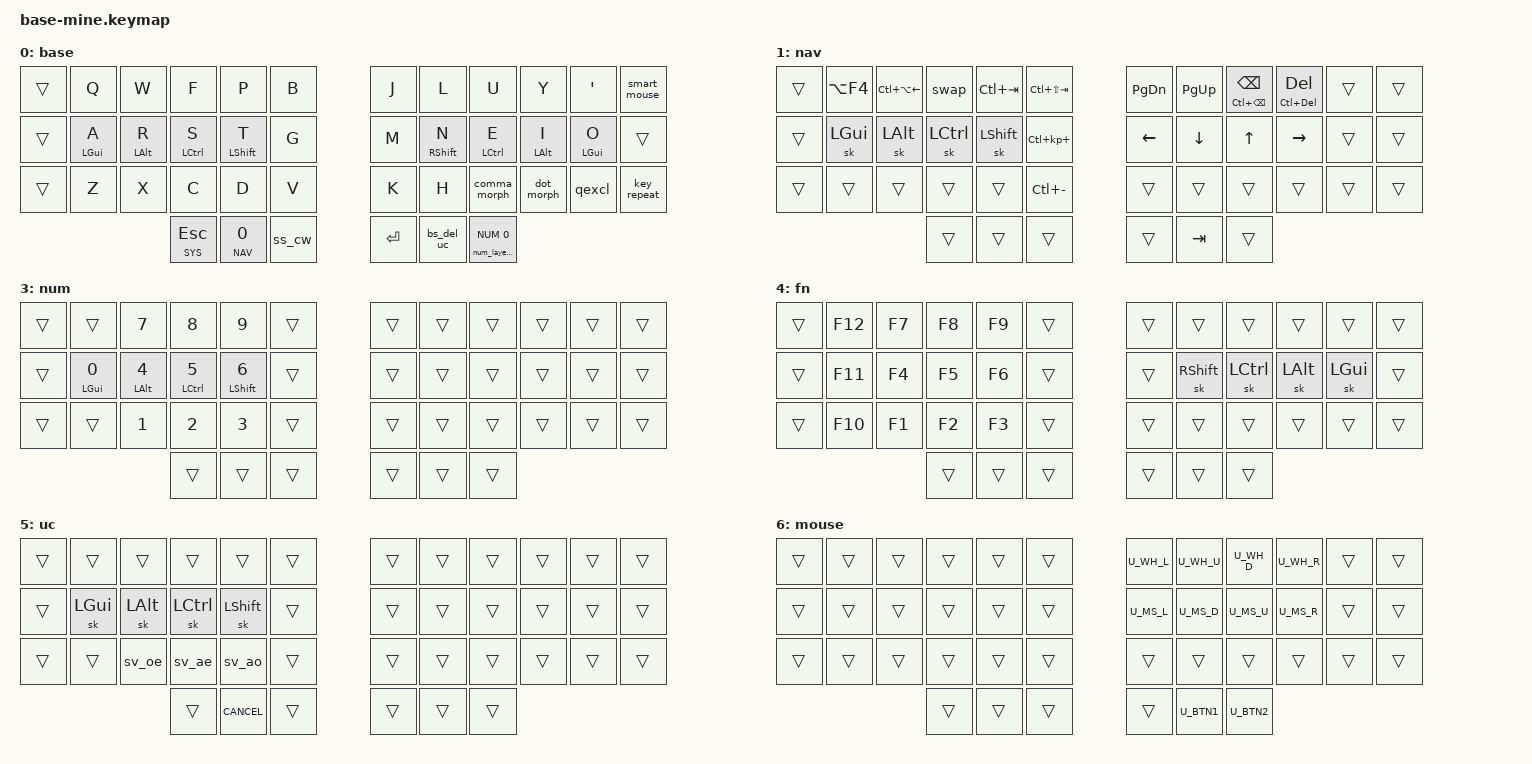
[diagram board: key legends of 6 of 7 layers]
#include <behaviors.dtsi>
#include <dt-bindings/zmk/keys.h>

#if CONFIG_WIRELESS
    #include <dt-bindings/zmk/bt.h>
    #define _BT_SEL_KEYS_ &bt BT_SEL 0 &bt BT_SEL 1 &bt BT_SEL 2 &bt BT_SEL 3 &bt BT_CLR
#else
    #define _BT_SEL_KEYS_ &trans &trans &trans &trans &trans
#endif

#include "../zmk-nodefree-config/helper.h"
// #include "../zmk-nodefree-config/international_chars/swedish.dtsi"
#include "../config/sv.dtsi"
// #include "../config/sv_osx.dtsi"

#define DEF 0
#define NAV 1
#define SYS 2
#define NUM 3
#define FN 4
#define UC 5
#define MOUSE 6

#include "combos.dtsi"  // must be sourced after layer-shortcuts
#include "mouse.dtsi"
#include "extra_keys.h"
// ZMK_CONDITIONAL_LAYER(NUM NAV, MOUSE)  // SYS + NAV --> MOUSE

/* Navigation keys and misc shortcuts */

&mt {
    flavor = "tap-preferred";
    tapping-term-ms = <220>;
    quick-tap-ms = <220>;              // repeat on tap-into-hold
    hold-trigger-key-positions = <0>;  // tap on interrupt
};

#define NAV_LEFT  &mt HOME     LEFT    // tap: left  | long-tap: beginning of line
#define NAV_RIGHT &mt END      RIGHT   // tap: right | long-tap: end       of line
#define NAV_UP    &mt LC(HOME) UP      // tap: up    | long-tap: beginning of document
#define NAV_DOWN  &mt LC(END)  DOWN    // tap: down  | long-tap: end       of document
#define NAV_BSPC  &mt LC(BSPC) BSPC    // tap: bspc  | long-tap: delete word backward
#define NAV_DEL   &mt LC(DEL)  DEL     // tap: del   | long-tap: delete word forward

#define XXX &none
#define ___ &trans

#define CANCEL      &kp K_CANCEL             // cancel caps-word, num-word and smart-mouse
#define DSK_PREV    &hmr RSHFT LG(LC(LEFT))  // previous desktop
#define DSK_NEXT    &hmr LALT LG(LC(RIGHT))  // next     desktop
#define VOL_DOWN    &hmr LCTRL C_VOL_DN

#define SPLIT_DOWN  &kp LS(LA(DOWN))
#define SPLIT_RIGHT &kp LS(LA(RIGHT))
#define SPLIT_LEFT  &kp LS(LA(LEFT))
#define SPLIT_UP    &kp LS(LA(UP))
#define FONT_PLUS   &kp LC(KP_PLUS)
#define FONT_MINUS  &kp LC(MINUS)
#define WIN_CLOSE   &kp LA(F4)
// #define WIN_LEFT    &kp LG(LC(LA(LEFT)))

// Window management
#define WIN_LEFT   &kp LC(LA(LEFT))
#define WIN_RIGHT  &kp LC(LA(RIGHT))
#define WIN_DOWN   &kp LC(LA(DOWN))
#define WIN_UP     &kp LC(LA(UP))
#define WIN_BIG    &kp LC(LA(ENTER))

/* Settings */

#define QUICK_TAP_MS 175

&sk {  // sticky-key config
    release-after-ms = <600>;  // release after 0.6s
    // quick-release;             // no double capitalization when rolling keys
};
&sl {  // sticky-layer config
    ignore-modifiers;
};

&lt {  // layer-tap config
    flavor = "balanced";
    tapping-term-ms = <200>;
    quick-tap-ms = <QUICK_TAP_MS>;
};

&caps_word {  // mods deactivate caps-word, requires PR #1441
    /delete-property/ ignore-modifiers;
};

&num_word {  // num-word, requires PR #1441
    layers = <NUM>;
};

/* Homerow mods */

#define KEYS_L LT0 LT1 LT2 LT3 LT4 LT5 LM0 LM1 LM2 LM3 LM4 LM5 LB0 LB1 LB2 LB3 LB4 LB5 // left-hand keys
#define KEYS_R RT0 RT1 RT2 RT3 RT4 RT5 RM0 RM1 RM2 RM3 RM4 LM5 RB0 RB1 RB2 RB3 RB4 LB5 // right-hand keys
#define THUMBS LH2 LH1 LH0 RH0 RH1 RH2                                      // thumb keys

ZMK_BEHAVIOR(hml, hold_tap,  // left-hand HRMs
    flavor = "balanced";
    tapping-term-ms = <280>;
    quick-tap-ms = <QUICK_TAP_MS>;
    global-quick-tap-ms = <150>;        // requires PR #1387
    bindings = <&kp>, <&kp>;
    hold-trigger-key-positions = <KEYS_R THUMBS>;
    hold-trigger-on-release;            // requires PR #1423
)

ZMK_BEHAVIOR(hmr, hold_tap,  // right-hand HRMs
    flavor = "balanced";
    tapping-term-ms = <280>;
    quick-tap-ms = <QUICK_TAP_MS>;
    global-quick-tap-ms = <150>;        // requires PR #1387
    bindings = <&kp>, <&kp>;
    hold-trigger-key-positions = <KEYS_L THUMBS>;
    hold-trigger-on-release;            // requires PR #1423
)

/* Custom behaviors */

// tap: num-word | double-tap: sticky num-layer | hold: num-layer
ZMK_BEHAVIOR(num_dance, tap_dance,
    tapping-term-ms = <200>;
    bindings = <&num_word>, <&sl NUM>;  // might want to reverse if rarely using more than 1 digit
)
ZMK_BEHAVIOR(num_layer_word, hold_tap,
    flavor = "balanced";
    tapping-term-ms = <200>;
    quick-tap-ms = <QUICK_TAP_MS>;
    bindings = <&mo>, <&num_dance>;
)
#define NUM_WORD &num_layer_word NUM 0

ZMK_BEHAVIOR(skq, sticky_key,
    bindings = <&kp>;
    release-after-ms = <1000>;
    quick-release;
)
// mouse layer that deactivates automatically on all other keys, requires PR #1366
ZMK_BEHAVIOR(smart_mouse, tri_state,
    bindings = <&tog MOUSE>, <&none>, <&tog MOUSE>;
    ignored-key-positions = <RT1 RT2 RM0 RM1 RM2 RM3 RH1 RH2>;  // mouse keys
    ignored-layers = <MOUSE>;
)

// tap: sticky-shift | shift + tap/ double-tap: caps-word | hold: shift
ZMK_BEHAVIOR(ss_cw, mod_morph,
    bindings = <&skq LSHFT>, <&caps_word>;
    mods = <(MOD_LSFT)>;
)

// tap: backspace | lshft + tap: delete | rshft + tap: shift-delete | hold: num layer
ZMK_BEHAVIOR(bs_del_uc, mod_morph,
    bindings = <&lt UC BSPC>, <&kp DEL>;
    mods = <(MOD_LSFT|MOD_RSFT)>;
    keep-mods = <MOD_RSFT>;
)

// tap: space | shift + tap: dot -> space -> sticky shift | hold: activate layer
ZMK_BEHAVIOR(dot_spc, macro,
    wait-ms = <0>;
    tap-ms = <5>;
    bindings = <&kp DOT &kp SPACE &sk LSHFT>;
)

ZMK_BEHAVIOR(spc_morph, mod_morph,
    bindings = <&kp SPACE>, <&dot_spc>;
    mods = <(MOD_LSFT|MOD_RSFT)>;
)


ZMK_BEHAVIOR(lt_spc, hold_tap,
    flavor = "balanced";
    tapping-term-ms = <200>;
    quick-tap-ms = <QUICK_TAP_MS>;
    bindings = <&mo>, <&spc_morph>;
)

// tap: copy | double-tap: cut
ZMK_BEHAVIOR(copy_cut, tap_dance,
    tapping-term-ms = <200>;
    bindings = <&kp LC(INS)>, <&kp LC(X)>;
)

// Windows sleep key
ZMK_BEHAVIOR(win_sleep, macro,
    wait-ms = <100>;
    tap-ms = <5>;
    bindings = <&kp LG(X) &kp U &kp S>;
)

// Sticky layer + sticky shift (workaround for issue #1421)
ZMK_BEHAVIOR(uc_shift, macro,
    wait-ms = <0>;
    tap-ms = <1>;
    bindings = <&macro_press &mo UC &kp LSHFT>
             , <&macro_pause_for_release>
             , <&macro_release &mo UC &kp LSHFT>;
)
ZMK_BEHAVIOR(sls, sticky_key,
    release-after-ms = <1000>;
    bindings = <&uc_shift>;
    ignore-modifiers;
)

// tap: comma | shift + tap: semicolon | ctrl + shift + tap: <
ZMK_BEHAVIOR(comma_inner_morph, mod_morph,
    bindings = <&kp SEMICOLON>, <&kp LESS_THAN>;
    mods = <(MOD_LCTL|MOD_RCTL)>;
)
ZMK_BEHAVIOR(comma_morph, mod_morph,
    mods = <(MOD_LSFT|MOD_RSFT)>;
    bindings = <&kp COMMA>, <&comma_inner_morph>;
)

// tap: dot | shift + tap: colon | ctrl + shift + tap: >
ZMK_BEHAVIOR(dot_inner_morph, mod_morph,
    bindings = <&kp COLON>, <&kp GREATER_THAN>;
    mods = <(MOD_LCTL|MOD_RCTL)>;
)
ZMK_BEHAVIOR(dot_morph, mod_morph,
    bindings = <&kp DOT>, <&dot_inner_morph>;
    mods = <(MOD_LSFT|MOD_RSFT)>;
)

// tap: qmark | shift + tap: excl
ZMK_BEHAVIOR(qexcl, mod_morph,
    bindings = <&kp QMARK>, <&kp EXCL>;
    mods = <(MOD_LSFT|MOD_RSFT)>;
)

// Alt+Tab swapper, requires PR #1366
ZMK_BEHAVIOR(swap, tri_state,
    bindings = <&kt LALT>, <&kp TAB>, <&kt LALT>;
    ignored-key-positions = <LT2>;
)

/* Keymap */
ZMK_LAYER(base,
     // ╭─────────────┬─────────────┬─────────────┬─────────────┬─────────────┬─────────────╮   ╭─────────────┬─────────────┬─────────────┬─────────────┬─────────────┬─────────────╮
              ___          &kp Q         &kp W         &kp F         &kp P         &kp B            &kp J          &kp L         &kp U        &kp Y         &kp SQT    &smart_mouse  
     // ├─────────────├─────────────┼─────────────┼─────────────┼─────────────┼─────────────┤   ├─────────────┼─────────────┼─────────────┼─────────────┼─────────────┼─────────────┤
              ___       &hml LGUI A   &hml LALT R   &hml LCTRL S  &hml LSHFT T     &kp G            &kp M       &hmr RSHFT N  &hmr LCTRL E  &hmr LALT I   &hmr LGUI O       ___  
     // ├─────────────├─────────────┼─────────────┼─────────────┼─────────────┼─────────────┤   ├─────────────┼─────────────┼─────────────┼─────────────┼─────────────┼─────────────┤
              ___          &kp Z         &kp X         &kp C         &kp D         &kp V            &kp K          &kp H      &comma_morph   &dot_morph     &qexcl      &key_repeat
     // ├─────────────├─────────────┼─────────────┼─────────────┼─────────────┼─────────────┤   ├─────────────┼─────────────┼─────────────┼─────────────┼─────────────┼─────────────┤
                                                    &lt SYS ESC  &lt_spc NAV 0     &ss_cw          &kp ENTER     &bs_del_uc     NUM_WORD
     //                                           ╰─────────────┴─────────────┴─────────────╯   ╰─────────────┴─────────────┴─────────────╯
)

ZMK_LAYER(nav,
     // ╭─────────────┬─────────────┬─────────────┬─────────────┬─────────────┬─────────────╮   ╭─────────────┬─────────────┬─────────────┬─────────────┬─────────────┬─────────────╮
              ___         WIN_CLOSE     WIN_LEFT       &swap      &kp LC(TAB)  &kp LC(LS(TAB))     &kp PG_DN      &kp PG_UP    NAV_BSPC       NAV_DEL         ___           ___
     // ├─────────────├─────────────┼─────────────┼─────────────┼─────────────┼─────────────┤   ├─────────────┼─────────────┼─────────────┼─────────────┼─────────────┼─────────────┤
              ___         &sk LGUI      &sk LALT    &sk LCTRL     &sk LSHFT      FONT_PLUS         &kp LEFT       &kp DOWN      &kp UP       &kp RIGHT        ___           ___ 
     // ├─────────────├─────────────┼─────────────┼─────────────┼─────────────┼─────────────┤   ├─────────────┼─────────────┼─────────────┼─────────────┼─────────────┼─────────────┤
              ___           ___           ___           ___           ___        FONT_MINUS          ___            ___          ___           ___            ___           ___     
     // ├─────────────├─────────────┼─────────────┼─────────────┼─────────────┼─────────────┤   ├─────────────┼─────────────┼─────────────┼─────────────┼─────────────┼─────────────┤
                                                        ___           ___           ___              ___          &kp TAB        ___
     //                                           ╰─────────────┴─────────────┴─────────────╯   ╰─────────────┴─────────────┴─────────────╯
)

ZMK_LAYER(sys,
     // ╭─────────────┬─────────────┬─────────────┬─────────────┬─────────────┬─────────────╮   ╭─────────────┬─────────────┬─────────────┬─────────────┬─────────────┬─────────────╮
              ___                                  _BT_SEL_KEYS_                                      ___      &kp C_VOL_DN   &kp C_VOL_UP      ___           ___           ___
     // ├─────────────├─────────────┼─────────────┼─────────────┼─────────────┼─────────────┤   ├─────────────┼─────────────┼─────────────┼─────────────┼─────────────┼─────────────┤
              ___        &sk LGUI      &sk LALT      &sk LCTRL     &sk LSHFT        ___             WIN_LEFT     WIN_DOWN        WIN_UP       WIN_RIGHT       ___           ___
     // ├─────────────├─────────────┼─────────────┼─────────────┼─────────────┼─────────────┤   ├─────────────┼─────────────┼─────────────┼─────────────┼─────────────┼─────────────┤
              ___           ___          ___            ___           ___           ___            SPLIT_LEFT   SPLIT_DOWN      SPLIT_UP    SPLIT_RIGHT       ___           ___
     // ├─────────────├─────────────┼─────────────┼─────────────┼─────────────┼─────────────┤   ├─────────────┼─────────────┼─────────────┼─────────────┼─────────────┼─────────────┤
                                                        ___           ___           ___             WIN_BIG      &kp C_PP     &kp C_MUTE
     //                                           ╰─────────────┴─────────────┴─────────────╯   ╰─────────────┴─────────────┴─────────────╯
)

ZMK_LAYER(num, 
     // ╭─────────────┬─────────────┬─────────────┬─────────────┬─────────────┬─────────────╮   ╭─────────────┬─────────────┬─────────────┬─────────────┬─────────────┬─────────────╮
              ___           ___          &kp N7        &kp N8        &kp N9         ___               ___           ___           ___           ___          ___           ___
     // ├─────────────├─────────────┼─────────────┼─────────────┼─────────────┼─────────────┤   ├─────────────┼─────────────┼─────────────┼─────────────┼─────────────┼─────────────┤
              ___       &hml LGUI N0  &hml LALT N4 &hml LCTRL N5 &hml LSHFT N6      ___               ___           ___           ___           ___          ___           ___
     // ├─────────────├─────────────┼─────────────┼─────────────┼─────────────┼─────────────┤   ├─────────────┼─────────────┼─────────────┼─────────────┼─────────────┼─────────────┤
              ___           ___          &kp N1        &kp N2        &kp N3         ___               ___           ___           ___           ___          ___           ___
     // ├─────────────├─────────────┼─────────────┼─────────────┼─────────────┼─────────────┤   ├─────────────┼─────────────┼─────────────┼─────────────┼─────────────┼─────────────┤
                                                        ___           ___           ___               ___           ___           ___
     //                                           ╰─────────────┴─────────────┴─────────────╯   ╰─────────────┴─────────────┴─────────────╯
)
//
// ZMK_LAYER(sym,
//      // ╭─────────────┬─────────────┬─────────────┬─────────────┬─────────────┬─────────────╮   ╭─────────────┬─────────────┬─────────────┬─────────────┬─────────────┬─────────────╮
//               ___           ___         &kp LBRC     &kp AMPS      &kp RBRC         ___               ___           ___           ___           ___            ___           ___ 
//      // ├─────────────├─────────────┼─────────────┼─────────────┼─────────────┼─────────────┤   ├─────────────┼─────────────┼─────────────┼─────────────┼─────────────┼─────────────┤
//               ___           ___         &kp LPAR     &kp PRCT      &kp RPAR      &kp PLUS             ___           ___           ___           ___            ___           ___
//      // ├─────────────├─────────────┼─────────────┼─────────────┼─────────────┼─────────────┤   ├─────────────┼─────────────┼─────────────┼─────────────┼─────────────┼─────────────┤
//               ___           ___         &kp LBKT      &kp AT       &kp RBKT      &kp BSLH             ___           ___           ___           ___            ___           ___
//      // ├─────────────├─────────────┼─────────────┼─────────────┼─────────────┼─────────────┤   ├─────────────┼─────────────┼─────────────┼─────────────┼─────────────┼─────────────┤
//                                                       CANCEL       &kp UNDER     &kp MINUS            ___           ___           ___
//      //                                           ╰─────────────┴─────────────┴─────────────╯   ╰─────────────┴─────────────┴─────────────╯
// )

ZMK_LAYER(fn,
     // ╭─────────────┬─────────────┬─────────────┬─────────────┬─────────────┬─────────────╮   ╭─────────────┬─────────────┬─────────────┬─────────────┬─────────────┬─────────────╮
              ___          &kp F12       &kp F7        &kp F8        &kp F9         ___                ___           ___           ___           ___           ___           ___
     // ├─────────────├─────────────┼─────────────┼─────────────┼─────────────┼─────────────┤   ├─────────────┼─────────────┼─────────────┼─────────────┼─────────────┼─────────────┤
              ___          &kp F11       &kp F4        &kp F5        &kp F6         ___                ___       &sk RSHFT     &sk LCTRL     &sk LALT      &sk LGUI          ___
     // ├─────────────├─────────────┼─────────────┼─────────────┼─────────────┼─────────────┤   ├─────────────┼─────────────┼─────────────┼─────────────┼─────────────┼─────────────┤
              ___          &kp F10       &kp F1        &kp F2        &kp F3         ___                ___           ___           ___           ___           ___           ___
     // ├─────────────├─────────────┼─────────────┼─────────────┼─────────────┼─────────────┤   ├─────────────┼─────────────┼─────────────┼─────────────┼─────────────┼─────────────┤
                                                        ___           ___           ___                ___           ___           ___
     //                                           ╰─────────────┴─────────────┴─────────────╯   ╰─────────────┴─────────────┴─────────────╯
)

ZMK_LAYER(uc,
     // ╭─────────────┬─────────────┬─────────────┬─────────────┬─────────────┬─────────────╮   ╭─────────────┬─────────────┬─────────────┬─────────────┬─────────────┬─────────────╮
              ___           ___           ___           ___           ___           ___                ___           ___           ___           ___           ___           ___
     // ├─────────────├─────────────┼─────────────┼─────────────┼─────────────┼─────────────┤   ├─────────────┼─────────────┼─────────────┼─────────────┼─────────────┼─────────────┤
              ___         &sk LGUI      &sk LALT     &sk LCTRL      &sk LSHFT       ___                ___           ___           ___           ___           ___           ___
     // ├─────────────├─────────────┼─────────────┼─────────────┼─────────────┼─────────────┤   ├─────────────┼─────────────┼─────────────┼─────────────┼─────────────┼─────────────┤
              ___           ___          &sv_oe        &sv_ae        &sv_ao         ___                ___           ___           ___           ___           ___           ___ 
     // ├─────────────├─────────────┼─────────────┼─────────────┼─────────────┼─────────────┤   ├─────────────┼─────────────┼─────────────┼─────────────┼─────────────┼─────────────┤
                                                        ___          CANCEL         ___                ___           ___           ___
     //                                           ╰─────────────┴─────────────┴─────────────╯   ╰─────────────┴─────────────┴─────────────╯
)

ZMK_LAYER(mouse,
     // ╭─────────────┬─────────────┬─────────────┬─────────────┬─────────────┬─────────────╮   ╭─────────────┬─────────────┬─────────────┬─────────────┬─────────────┬─────────────╮
              ___           ___           ___           ___           ___           ___              U_WH_L        U_WH_U        U_WH_D        U_WH_R         ___           ___
     // ├─────────────├─────────────┼─────────────┼─────────────┼─────────────┼─────────────┤   ├─────────────┼─────────────┼─────────────┼─────────────┼─────────────┼─────────────┤
              ___           ___           ___           ___           ___           ___              U_MS_L        U_MS_D        U_MS_U        U_MS_R         ___           ___
     // ├─────────────├─────────────┼─────────────┼─────────────┼─────────────┼─────────────┤   ├─────────────┼─────────────┼─────────────┼─────────────┼─────────────┼─────────────┤
              ___           ___           ___           ___           ___           ___               ___           ___           ___           ___           ___           ___
     // ├─────────────├─────────────┼─────────────┼─────────────┼─────────────┼─────────────┤   ├─────────────┼─────────────┼─────────────┼─────────────┼─────────────┼─────────────┤
                                                        ___           ___           ___               ___          U_BTN1        U_BTN2
     //                                           ╰─────────────┴─────────────┴─────────────╯   ╰─────────────┴─────────────┴─────────────╯
)

/* vim: set ft=cpp tw=174: */
